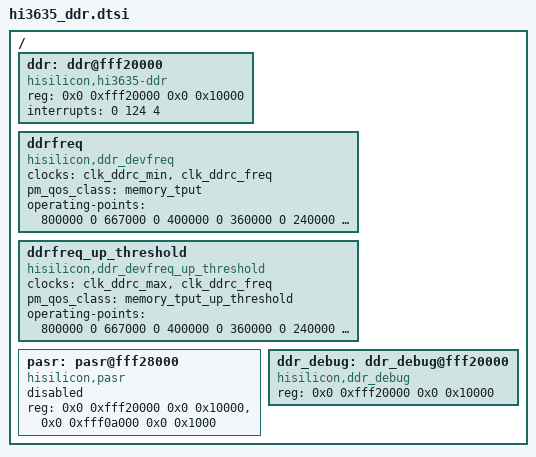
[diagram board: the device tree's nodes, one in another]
/*
 * Hisilicon Ltd. Hi3635 SoC
 *
 * Copyright (C) 2012-2014 Hisilicon Ltd.
 *
 * This program is free software; you can redistribute it and/or modify
 * it under the terms of the GNU General Public License version 2 as
 * publishhed by the Free Software Foundation.
 */

/{

		ddr: ddr@fff20000 {
			#address-cells = <2>;
			#size-cells = <2>;
			compatible = "hisilicon,hi3635-ddr";
			reg = <0x0 0xfff20000 0x0 0x10000>;
			interrupts = <0 124 4>;
			status = "ok";
		};

		ddrfreq {
			#address-cells = <2>;
			#size-cells = <2>;
			compatible = "hisilicon,ddr_devfreq";
			clocks = <&clk_ddrc_min &clk_ddrc_freq>;
			pm_qos_class = "memory_tput";
			operating-points = <
				/* kHz uV */
				800000	0
				667000	0
				400000	0
				360000	0
				240000	0
				120000	0
			>;
			status = "ok";
		};

		ddrfreq_up_threshold {
			#address-cells = <2>;
			#size-cells = <2>;
			compatible = "hisilicon,ddr_devfreq_up_threshold";
			clocks = <&clk_ddrc_max &clk_ddrc_freq>;
			pm_qos_class = "memory_tput_up_threshold";
			operating-points = <
				/* kHz uV */
				800000	0
				667000	0
				400000	0
				360000	0
				240000	0
				120000	0
			>;
			status = "ok";
		};

		pasr: pasr@fff28000 { /* DDR Partial Area Self-Refresh */
			#address-cells = <2>;
			#size-cells = <2>;
			compatible = "hisilicon,pasr";
			reg = <0x0 0xfff20000 0x0 0x10000>,
				<0x0 0xfff0a000 0x0 0x1000>;
			status = "disabled";
		};

		ddr_debug: ddr_debug@fff20000 {
			#address-cells = <2>;
			#size-cells = <2>;
			compatible = "hisilicon,ddr_debug";
			reg = <0x0 0xfff20000 0x0 0x10000>;
			status = "ok";
		};
};
